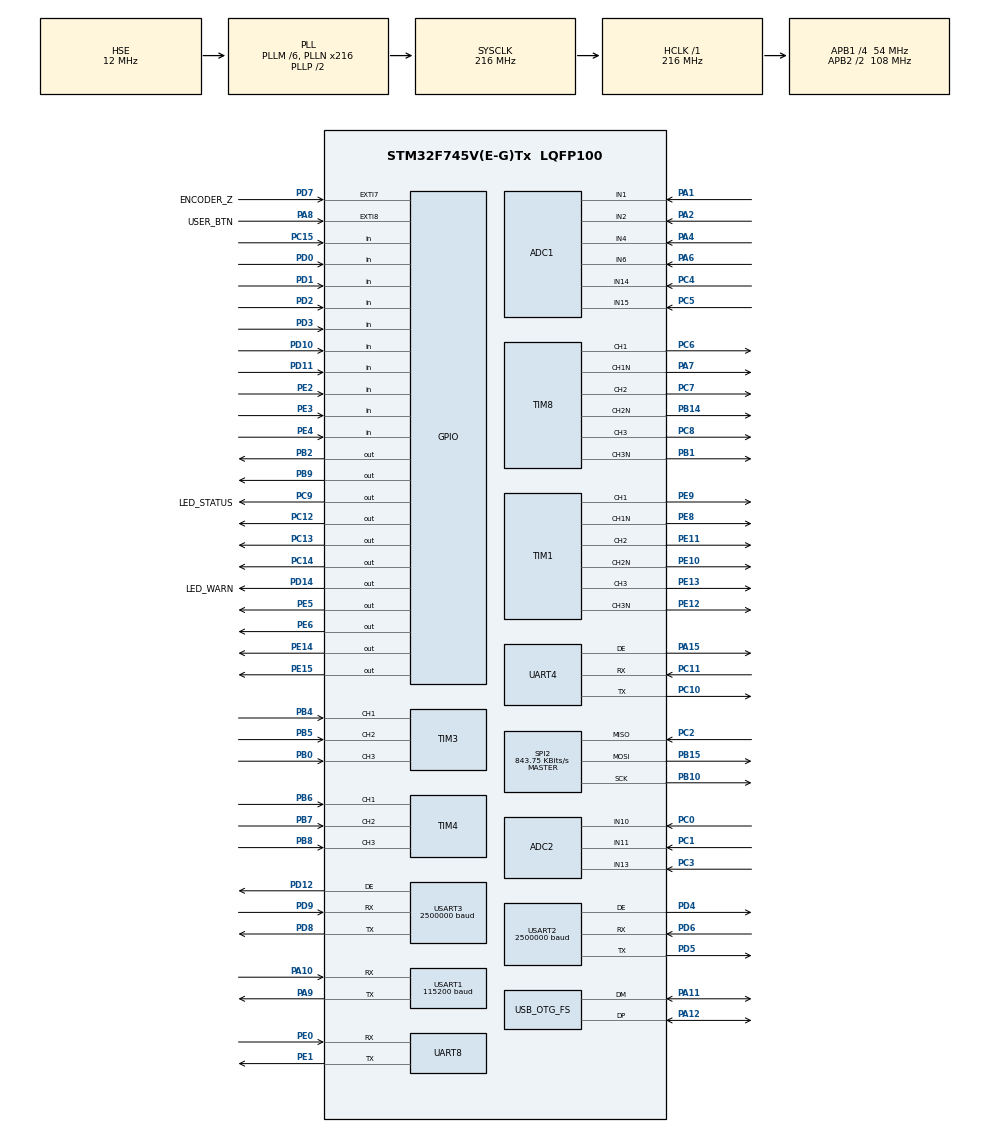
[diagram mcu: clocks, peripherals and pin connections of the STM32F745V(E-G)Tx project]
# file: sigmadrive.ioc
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ADC1.Channel-0\#ChannelRegularConversion=ADC_CHANNEL_1
ADC1.Channel-1\#ChannelInjectedConversion=ADC_CHANNEL_1
ADC1.Channel-10\#ChannelInjectedConversion=ADC_CHANNEL_4
ADC1.Channel-2\#ChannelInjectedConversion=ADC_CHANNEL_2
ADC1.Channel-5\#ChannelRegularConversion=ADC_CHANNEL_2
ADC1.Channel-6\#ChannelRegularConversion=ADC_CHANNEL_4
ADC1.Channel-7\#ChannelRegularConversion=ADC_CHANNEL_6
ADC1.Channel-8\#ChannelRegularConversion=ADC_CHANNEL_14
ADC1.Channel-9\#ChannelRegularConversion=ADC_CHANNEL_15
ADC1.ContinuousConvMode=DISABLE
ADC1.DMAContinuousRequests=ENABLE
ADC1.EOCSelection=ADC_EOC_SINGLE_CONV
ADC1.ExternalTrigConv=ADC_EXTERNALTRIGCONV_T1_TRGO2
ADC1.ExternalTrigConvEdge=ADC_EXTERNALTRIGCONVEDGE_RISINGFALLING
ADC1.ExternalTrigInjecConv=ADC_EXTERNALTRIGINJECCONV_T1_TRGO2
ADC1.ExternalTrigInjecConvEdge=ADC_EXTERNALTRIGINJECCONVEDGE_RISINGFALLING
ADC1.InjNumberOfConversion=3
ADC1.InjectedConvMode=None
ADC1.InjectedOffset-1\#ChannelInjectedConversion=0
ADC1.InjectedOffset-10\#ChannelInjectedConversion=0
ADC1.InjectedOffset-2\#ChannelInjectedConversion=0
ADC1.InjectedRank-1\#ChannelInjectedConversion=1
ADC1.InjectedRank-10\#ChannelInjectedConversion=3
ADC1.InjectedRank-2\#ChannelInjectedConversion=2
ADC1.NbrOfConversion=6
ADC1.NbrOfConversionFlag=1
ADC1.Rank-0\#ChannelRegularConversion=1
ADC1.Rank-5\#ChannelRegularConversion=2
ADC1.Rank-6\#ChannelRegularConversion=3
ADC1.Rank-7\#ChannelRegularConversion=4
ADC1.Rank-8\#ChannelRegularConversion=5
ADC1.Rank-9\#ChannelRegularConversion=6
ADC1.SamplingTime-0\#ChannelRegularConversion=ADC_SAMPLETIME_15CYCLES
ADC1.SamplingTime-1\#ChannelInjectedConversion=ADC_SAMPLETIME_15CYCLES
ADC1.SamplingTime-10\#ChannelInjectedConversion=ADC_SAMPLETIME_15CYCLES
ADC1.SamplingTime-2\#ChannelInjectedConversion=ADC_SAMPLETIME_15CYCLES
ADC1.SamplingTime-5\#ChannelRegularConversion=ADC_SAMPLETIME_15CYCLES
ADC1.SamplingTime-6\#ChannelRegularConversion=ADC_SAMPLETIME_15CYCLES
ADC1.SamplingTime-7\#ChannelRegularConversion=ADC_SAMPLETIME_15CYCLES
ADC1.SamplingTime-8\#ChannelRegularConversion=ADC_SAMPLETIME_15CYCLES
ADC1.SamplingTime-9\#ChannelRegularConversion=ADC_SAMPLETIME_15CYCLES
ADC1.master=1
ADC2.Channel-10\#ChannelRegularConversion=ADC_CHANNEL_13
ADC2.Channel-11\#ChannelInjectedConversion=ADC_CHANNEL_10
ADC2.Channel-12\#ChannelInjectedConversion=ADC_CHANNEL_11
ADC2.Channel-13\#ChannelInjectedConversion=ADC_CHANNEL_13
ADC2.Channel-8\#ChannelRegularConversion=ADC_CHANNEL_10
ADC2.Channel-9\#ChannelRegularConversion=ADC_CHANNEL_11
ADC2.DMAContinuousRequests=ENABLE
ADC2.ExternalTrigConv=ADC_EXTERNALTRIGCONV_T8_TRGO2
ADC2.ExternalTrigConvEdge=ADC_EXTERNALTRIGCONVEDGE_RISINGFALLING
ADC2.ExternalTrigInjecConv=ADC_EXTERNALTRIGINJECCONV_T8_TRGO2
ADC2.ExternalTrigInjecConvEdge=ADC_EXTERNALTRIGINJECCONVEDGE_RISINGFALLING
ADC2.InjNumberOfConversion=3
ADC2.InjectedOffset-11\#ChannelInjectedConversion=0
ADC2.InjectedOffset-12\#ChannelInjectedConversion=0
ADC2.InjectedOffset-13\#ChannelInjectedConversion=0
ADC2.InjectedRank-11\#ChannelInjectedConversion=1
ADC2.InjectedRank-12\#ChannelInjectedConversion=2
ADC2.InjectedRank-13\#ChannelInjectedConversion=3
ADC2.NbrOfConversion=3
ADC2.NbrOfConversionFlag=1
ADC2.Rank-10\#ChannelRegularConversion=3
ADC2.Rank-8\#ChannelRegularConversion=1
ADC2.Rank-9\#ChannelRegularConversion=2
ADC2.SamplingTime-10\#ChannelRegularConversion=ADC_SAMPLETIME_15CYCLES
ADC2.SamplingTime-11\#ChannelInjectedConversion=ADC_SAMPLETIME_15CYCLES
ADC2.SamplingTime-12\#ChannelInjectedConversion=ADC_SAMPLETIME_15CYCLES
ADC2.SamplingTime-13\#ChannelInjectedConversion=ADC_SAMPLETIME_15CYCLES
ADC2.SamplingTime-8\#ChannelRegularConversion=ADC_SAMPLETIME_15CYCLES
ADC2.SamplingTime-9\#ChannelRegularConversion=ADC_SAMPLETIME_15CYCLES
ADC2.ScanConvMode=ADC_SCAN_ENABLE
ADC3.Channel-2\#ChannelRegularConversion=ADC_CHANNEL_2
ADC3.Channel-3\#ChannelInjectedConversion=ADC_CHANNEL_2
ADC3.ExternalTrigInjecConv=ADC_EXTERNALTRIGINJECCONV_T1_TRGO
ADC3.ExternalTrigInjecConvEdge=ADC_EXTERNALTRIGINJECCONVEDGE_RISINGFALLING
ADC3.InjNumberOfConversion=1
ADC3.InjectedOffset-3\#ChannelInjectedConversion=0
ADC3.InjectedRank-3\#ChannelInjectedConversion=1
ADC3.NbrOfConversion=1
ADC3.NbrOfConversionFlag=1
ADC3.Rank-2\#ChannelRegularConversion=1
ADC3.SamplingTime-2\#ChannelRegularConversion=ADC_SAMPLETIME_3CYCLES
ADC3.SamplingTime-3\#ChannelInjectedConversion=ADC_SAMPLETIME_15CYCLES
CORTEX_M7.CPU_DCache=Disabled
CORTEX_M7.CPU_ICache=Enabled
CORTEX_M7.PREFETCH_ENABLE=1
Dma.ADC1.2.Direction=DMA_PERIPH_TO_MEMORY
Dma.ADC1.2.FIFOMode=DMA_FIFOMODE_ENABLE
Dma.ADC1.2.FIFOThreshold=DMA_FIFO_THRESHOLD_HALFFULL
Dma.ADC1.2.Instance=DMA2_Stream0
Dma.ADC1.2.MemBurst=DMA_MBURST_SINGLE
Dma.ADC1.2.MemDataAlignment=DMA_MDATAALIGN_WORD
Dma.ADC1.2.MemInc=DMA_MINC_ENABLE
Dma.ADC1.2.Mode=DMA_CIRCULAR
Dma.ADC1.2.PeriphBurst=DMA_PBURST_SINGLE
Dma.ADC1.2.PeriphDataAlignment=DMA_PDATAALIGN_WORD
Dma.ADC1.2.PeriphInc=DMA_PINC_DISABLE
Dma.ADC1.2.Priority=DMA_PRIORITY_HIGH
Dma.ADC2.5.Direction=DMA_PERIPH_TO_MEMORY
Dma.ADC2.5.FIFOMode=DMA_FIFOMODE_ENABLE
Dma.ADC2.5.FIFOThreshold=DMA_FIFO_THRESHOLD_FULL
Dma.ADC2.5.Instance=DMA2_Stream2
Dma.ADC2.5.MemBurst=DMA_MBURST_SINGLE
Dma.ADC2.5.MemDataAlignment=DMA_MDATAALIGN_WORD
Dma.ADC2.5.MemInc=DMA_MINC_ENABLE
Dma.ADC2.5.Mode=DMA_CIRCULAR
Dma.ADC2.5.PeriphBurst=DMA_PBURST_SINGLE
Dma.ADC2.5.PeriphDataAlignment=DMA_PDATAALIGN_WORD
Dma.ADC2.5.PeriphInc=DMA_PINC_DISABLE
Dma.ADC2.5.Priority=DMA_PRIORITY_LOW
Dma.Request0=USART1_TX
Dma.Request1=USART1_RX
Dma.Request2=ADC1
Dma.Request3=USART3_RX
Dma.Request4=USART2_RX
Dma.Request5=ADC2
Dma.Request6=UART4_RX
Dma.Request7=UART4_TX
Dma.Request8=UART8_TX
Dma.Request9=UART8_RX
Dma.UART4_RX.6.Direction=DMA_PERIPH_TO_MEMORY
Dma.UART4_RX.6.FIFOMode=DMA_FIFOMODE_DISABLE
Dma.UART4_RX.6.Instance=DMA1_Stream2
Dma.UART4_RX.6.MemDataAlignment=DMA_MDATAALIGN_BYTE
Dma.UART4_RX.6.MemInc=DMA_MINC_ENABLE
Dma.UART4_RX.6.Mode=DMA_CIRCULAR
Dma.UART4_RX.6.PeriphDataAlignment=DMA_PDATAALIGN_BYTE
Dma.UART4_RX.6.PeriphInc=DMA_PINC_DISABLE
Dma.UART4_RX.6.Priority=DMA_PRIORITY_LOW
Dma.UART4_TX.7.Direction=DMA_MEMORY_TO_PERIPH
Dma.UART4_TX.7.FIFOMode=DMA_FIFOMODE_DISABLE
Dma.UART4_TX.7.Instance=DMA1_Stream4
Dma.UART4_TX.7.MemDataAlignment=DMA_MDATAALIGN_BYTE
Dma.UART4_TX.7.MemInc=DMA_MINC_ENABLE
Dma.UART4_TX.7.Mode=DMA_NORMAL
Dma.UART4_TX.7.PeriphDataAlignment=DMA_PDATAALIGN_BYTE
Dma.UART4_TX.7.PeriphInc=DMA_PINC_DISABLE
Dma.UART4_TX.7.Priority=DMA_PRIORITY_LOW
Dma.UART8_RX.9.Direction=DMA_PERIPH_TO_MEMORY
Dma.UART8_RX.9.FIFOMode=DMA_FIFOMODE_DISABLE
Dma.UART8_RX.9.Instance=DMA1_Stream6
Dma.UART8_RX.9.MemDataAlignment=DMA_MDATAALIGN_BYTE
Dma.UART8_RX.9.MemInc=DMA_MINC_ENABLE
Dma.UART8_RX.9.Mode=DMA_CIRCULAR
Dma.UART8_RX.9.PeriphDataAlignment=DMA_PDATAALIGN_BYTE
Dma.UART8_RX.9.PeriphInc=DMA_PINC_DISABLE
Dma.UART8_RX.9.Priority=DMA_PRIORITY_LOW
Dma.UART8_TX.8.Direction=DMA_MEMORY_TO_PERIPH
Dma.UART8_TX.8.FIFOMode=DMA_FIFOMODE_DISABLE
Dma.UART8_TX.8.Instance=DMA1_Stream0
Dma.UART8_TX.8.MemDataAlignment=DMA_MDATAALIGN_BYTE
Dma.UART8_TX.8.MemInc=DMA_MINC_ENABLE
Dma.UART8_TX.8.Mode=DMA_NORMAL
Dma.UART8_TX.8.PeriphDataAlignment=DMA_PDATAALIGN_BYTE
Dma.UART8_TX.8.PeriphInc=DMA_PINC_DISABLE
Dma.UART8_TX.8.Priority=DMA_PRIORITY_LOW
Dma.USART1_RX.1.Direction=DMA_PERIPH_TO_MEMORY
Dma.USART1_RX.1.FIFOMode=DMA_FIFOMODE_DISABLE
Dma.USART1_RX.1.Instance=DMA2_Stream5
Dma.USART1_RX.1.MemDataAlignment=DMA_MDATAALIGN_BYTE
Dma.USART1_RX.1.MemInc=DMA_MINC_ENABLE
Dma.USART1_RX.1.Mode=DMA_CIRCULAR
Dma.USART1_RX.1.PeriphDataAlignment=DMA_PDATAALIGN_BYTE
Dma.USART1_RX.1.PeriphInc=DMA_PINC_DISABLE
Dma.USART1_RX.1.Priority=DMA_PRIORITY_LOW
Dma.USART1_TX.0.Direction=DMA_MEMORY_TO_PERIPH
Dma.USART1_TX.0.FIFOMode=DMA_FIFOMODE_DISABLE
Dma.USART1_TX.0.Instance=DMA2_Stream7
Dma.USART1_TX.0.MemDataAlignment=DMA_MDATAALIGN_BYTE
Dma.USART1_TX.0.MemInc=DMA_MINC_ENABLE
Dma.USART1_TX.0.Mode=DMA_NORMAL
Dma.USART1_TX.0.PeriphDataAlignment=DMA_PDATAALIGN_BYTE
Dma.USART1_TX.0.PeriphInc=DMA_PINC_DISABLE
Dma.USART1_TX.0.Priority=DMA_PRIORITY_LOW
Dma.USART2_RX.4.Direction=DMA_PERIPH_TO_MEMORY
Dma.USART2_RX.4.FIFOMode=DMA_FIFOMODE_DISABLE
Dma.USART2_RX.4.Instance=DMA1_Stream5
Dma.USART2_RX.4.MemDataAlignment=DMA_MDATAALIGN_BYTE
Dma.USART2_RX.4.MemInc=DMA_MINC_ENABLE
Dma.USART2_RX.4.Mode=DMA_NORMAL
Dma.USART2_RX.4.PeriphDataAlignment=DMA_PDATAALIGN_BYTE
Dma.USART2_RX.4.PeriphInc=DMA_PINC_DISABLE
Dma.USART2_RX.4.Priority=DMA_PRIORITY_VERY_HIGH
Dma.USART3_RX.3.Direction=DMA_PERIPH_TO_MEMORY
Dma.USART3_RX.3.FIFOMode=DMA_FIFOMODE_DISABLE
Dma.USART3_RX.3.Instance=DMA1_Stream1
Dma.USART3_RX.3.MemDataAlignment=DMA_MDATAALIGN_BYTE
Dma.USART3_RX.3.MemInc=DMA_MINC_ENABLE
Dma.USART3_RX.3.Mode=DMA_NORMAL
Dma.USART3_RX.3.PeriphDataAlignment=DMA_PDATAALIGN_BYTE
Dma.USART3_RX.3.PeriphInc=DMA_PINC_DISABLE
Dma.USART3_RX.3.Priority=DMA_PRIORITY_VERY_HIGH
FREERTOS.HEAP_NUMBER=3
FREERTOS.Tasks01=defaultTask,24,2048,StartDefaultTask,Default,NULL,Dynamic,NULL,NULL
FREERTOS.configMINIMAL_STACK_SIZE=1024
Mcu.Family=STM32F7
Mcu.Name=STM32F745V(E-G)Tx
Mcu.Package=LQFP100
Mcu.UserConstants=TIM1_PERIOD_CLOCKS,5400;TIM1_RCR,0;SYSTEM_CORE_CLOCK,216000000
NVIC.ADC_IRQn=true\:5\:0\:false\:false\:true\:true\:true\:true\:true
NVIC.DMA1_Stream0_IRQn=true\:5\:0\:false\:false\:true\:true\:false\:true\:true
NVIC.DMA1_Stream1_IRQn=true\:5\:0\:true\:false\:true\:false\:false\:true\:true
NVIC.DMA1_Stream2_IRQn=true\:5\:0\:true\:false\:true\:false\:false\:true\:true
NVIC.DMA1_Stream4_IRQn=true\:5\:0\:true\:false\:true\:false\:false\:true\:true
NVIC.DMA1_Stream5_IRQn=true\:5\:0\:true\:false\:true\:false\:false\:true\:true
NVIC.DMA1_Stream6_IRQn=true\:5\:0\:true\:false\:true\:false\:false\:true\:true
NVIC.DMA2_Stream0_IRQn=true\:5\:0\:false\:false\:true\:true\:false\:true\:true
NVIC.DMA2_Stream2_IRQn=true\:5\:0\:false\:false\:true\:true\:false\:true\:true
NVIC.DMA2_Stream5_IRQn=true\:5\:0\:false\:false\:true\:true\:false\:true\:true
NVIC.DMA2_Stream7_IRQn=true\:5\:0\:false\:false\:true\:true\:false\:true\:true
NVIC.EXTI9_5_IRQn=true\:2\:0\:true\:false\:true\:false\:true\:true\:true
NVIC.OTG_FS_IRQn=true\:5\:0\:true\:false\:true\:false\:false\:true\:true
NVIC.PriorityGroup=NVIC_PRIORITYGROUP_4
NVIC.TIM1_UP_TIM10_IRQn=true\:5\:0\:true\:false\:true\:false\:true\:true\:true
NVIC.TIM2_IRQn=true\:5\:0\:false\:false\:true\:true\:true\:true\:true
NVIC.TIM5_IRQn=true\:5\:0\:false\:false\:true\:true\:true\:true\:true
NVIC.TIM7_IRQn=true\:0\:0\:false\:false\:true\:false\:false\:true\:true
NVIC.TimeBase=TIM7_IRQn
NVIC.TimeBaseIP=TIM7
NVIC.UART4_IRQn=true\:5\:0\:true\:false\:true\:false\:true\:true\:true
NVIC.UART8_IRQn=true\:5\:0\:true\:false\:true\:false\:true\:true\:true
NVIC.USART1_IRQn=true\:5\:0\:false\:false\:true\:true\:true\:true\:true
NVIC.USART2_IRQn=true\:1\:0\:true\:false\:true\:false\:true\:true\:true
NVIC.USART3_IRQn=true\:1\:0\:true\:false\:true\:false\:true\:true\:true
PA0/WKUP.Signal=S_TIM5_CH1
PA1.Signal=ADCx_IN1
PA10.Mode=Asynchronous
PA10.Signal=USART1_RX
PA11.Mode=Device_Only
PA11.Signal=USB_OTG_FS_DM
PA12.Mode=Device_Only
PA12.Signal=USB_OTG_FS_DP
PA15.Mode=Hardware Flow Control (RS485)
PA15.Signal=UART4_DE
PA2.Signal=ADCx_IN2
PA4.Signal=ADCx_IN4
PA5.Signal=S_TIM2_CH1_ETR
PA6.Signal=ADCx_IN6
PA7.Mode=PWM Generation1 CH1 CH1N
PA7.Signal=TIM8_CH1N
PA8.GPIO_Label=USER_BTN
PA8.GPIO_ModeDefaultEXTI=GPIO_MODE_IT_FALLING
PA8.Signal=GPXTI8
PA9.Mode=Asynchronous
PA9.Signal=USART1_TX
PB0.Signal=S_TIM3_CH3
PB1.Mode=PWM Generation3 CH3 CH3N
PB1.Signal=TIM8_CH3N
PB10.Mode=Full_Duplex_Master
PB10.Signal=SPI2_SCK
PB14.Mode=PWM Generation2 CH2 CH2N
PB14.Signal=TIM8_CH2N
PB15.Mode=Full_Duplex_Master
PB15.Signal=SPI2_MOSI
PB2.GPIO_PuPd=GPIO_PULLUP
PB2.PinState=GPIO_PIN_SET
PB2.Signal=GPIO_Output
PB4.Signal=S_TIM3_CH1
PB5.Signal=S_TIM3_CH2
PB6.Signal=S_TIM4_CH1
PB7.Signal=S_TIM4_CH2
PB8.Signal=S_TIM4_CH3
PB9.Signal=GPIO_Output
PC0.Signal=ADCx_IN10
PC1.Signal=ADCx_IN11
PC10.Mode=Asynchronous
PC10.Signal=UART4_TX
PC11.Mode=Asynchronous
PC11.Signal=UART4_RX
PC12.Signal=GPIO_Output
PC13.GPIO_PuPd=GPIO_PULLUP
PC13.PinState=GPIO_PIN_SET
PC13.Signal=GPIO_Output
PC14/OSC32_IN.GPIO_ModeDefaultOutputPP=GPIO_MODE_OUTPUT_PP
PC14/OSC32_IN.GPIO_PuPd=GPIO_PULLUP
PC14/OSC32_IN.GPIO_Speed=GPIO_SPEED_FREQ_LOW
PC14/OSC32_IN.PinState=GPIO_PIN_SET
PC14/OSC32_IN.Signal=GPIO_Output
PC15/OSC32_OUT.GPIO_PuPd=GPIO_PULLUP
PC15/OSC32_OUT.Signal=GPIO_Input
PC2.GPIO_PuPd=GPIO_PULLUP
PC2.Mode=Full_Duplex_Master
PC2.Signal=SPI2_MISO
PC3.Signal=ADCx_IN13
PC4.Signal=ADCx_IN14
PC5.Signal=ADCx_IN15
PC6.Signal=S_TIM8_CH1
PC7.Signal=S_TIM8_CH2
PC8.Signal=S_TIM8_CH3
PC9.GPIO_Label=LED_STATUS
PC9.PinState=GPIO_PIN_SET
PC9.Signal=GPIO_Output
PD0.Signal=GPIO_Input
PD1.Signal=GPIO_Input
PD10.Signal=GPIO_Input
PD11.Signal=GPIO_Input
PD12.Mode=Hardware Flow Control (RS485)
PD12.Signal=USART3_DE
PD14.GPIO_Label=LED_WARN
PD14.GPIO_PuPd=GPIO_PULLUP
PD14.GPIO_Speed=GPIO_SPEED_FREQ_LOW
PD14.PinState=GPIO_PIN_RESET
PD14.Signal=GPIO_Output
PD2.Signal=GPIO_Input
PD3.Signal=GPIO_Input
PD4.Mode=Hardware Flow Control (RS485)
PD4.Signal=USART2_DE
PD5.Mode=Asynchronous
PD5.Signal=USART2_TX
PD6.Mode=Asynchronous
PD6.Signal=USART2_RX
PD7.GPIO_Label=ENCODER_Z
PD7.GPIO_ModeDefaultEXTI=GPIO_MODE_IT_RISING
PD7.GPIO_PuPd=GPIO_PULLDOWN
PD7.Signal=GPXTI7
PD8.Mode=Asynchronous
PD8.Signal=USART3_TX
PD9.Mode=Asynchronous
PD9.Signal=USART3_RX
PE0.Mode=Asynchronous
PE0.Signal=UART8_RX
PE1.Mode=Asynchronous
PE1.Signal=UART8_TX
PE10.Mode=PWM Generation2 CH2 CH2N
PE10.Signal=TIM1_CH2N
PE11.Signal=S_TIM1_CH2
PE12.Mode=PWM Generation3 CH3 CH3N
PE12.Signal=TIM1_CH3N
PE13.Signal=S_TIM1_CH3
PE14.PinState=GPIO_PIN_RESET
PE14.Signal=GPIO_Output
PE15.GPIO_PuPd=GPIO_PULLUP
PE15.PinState=GPIO_PIN_SET
PE15.Signal=GPIO_Output
PE2.Signal=GPIO_Input
PE3.Signal=GPIO_Input
PE4.Signal=GPIO_Input
PE5.Signal=GPIO_Output
PE6.Signal=GPIO_Output
PE8.Mode=PWM Generation1 CH1 CH1N
PE8.Signal=TIM1_CH1N
PE9.Signal=S_TIM1_CH1
PH0/OSC_IN.Mode=HSE-External-Oscillator
PH0/OSC_IN.Signal=RCC_OSC_IN
PH1/OSC_OUT.Mode=HSE-External-Oscillator
PH1/OSC_OUT.Signal=RCC_OSC_OUT
ProjectManager.HeapSize=0x200
ProjectManager.StackSize=0x400
ProjectManager.TargetToolchain=Makefile
RCC.AHBFreq_Value=216000000
RCC.APB1CLKDivider=RCC_HCLK_DIV4
RCC.APB1Freq_Value=54000000
RCC.APB1TimFreq_Value=108000000
RCC.APB2CLKDivider=RCC_HCLK_DIV2
RCC.APB2Freq_Value=108000000
RCC.APB2TimFreq_Value=216000000
RCC.CortexFreq_Value=216000000
RCC.HCLKFreq_Value=216000000
RCC.HSE_VALUE=12000000
RCC.HSI_VALUE=16000000
RCC.LSE_VALUE=32768
RCC.PLLM=6
RCC.PLLN=216
RCC.PLLQ=9
RCC.SYSCLKFreq_VALUE=216000000
RCC.SYSCLKSource=RCC_SYSCLKSOURCE_PLLCLK
RCC.USBFreq_Value=48000000
RCC.VCOOutputFreq_Value=432000000
SH.ADCx_IN1.0=ADC1_IN1,IN1
SH.ADCx_IN10.0=ADC2_IN10,IN10
SH.ADCx_IN11.0=ADC2_IN11,IN11
SH.ADCx_IN13.0=ADC2_IN13,IN13
SH.ADCx_IN14.0=ADC1_IN14,IN14
SH.ADCx_IN15.0=ADC1_IN15,IN15
SH.ADCx_IN2.0=ADC1_IN2,IN2
SH.ADCx_IN2.1=ADC3_IN2,IN2
SH.ADCx_IN4.0=ADC1_IN4,IN4
SH.ADCx_IN6.0=ADC1_IN6,IN6
SH.S_TIM1_CH1.0=TIM1_CH1,PWM Generation1 CH1 CH1N
SH.S_TIM1_CH2.0=TIM1_CH2,PWM Generation2 CH2 CH2N
SH.S_TIM1_CH3.0=TIM1_CH3,PWM Generation3 CH3 CH3N
SH.S_TIM2_CH1_ETR.0=TIM2_CH1
SH.S_TIM3_CH1.0=TIM3_CH1,Input_Capture1_from_TI1
SH.S_TIM3_CH2.0=TIM3_CH2,Input_Capture2_from_TI2
SH.S_TIM3_CH3.0=TIM3_CH3,Input_Capture3_from_TI3
SH.S_TIM4_CH1.0=TIM4_CH1,Input_Capture1_from_TI1
SH.S_TIM4_CH2.0=TIM4_CH2,Input_Capture2_from_TI2
SH.S_TIM4_CH3.0=TIM4_CH3,Input_Capture3_from_TI3
SH.S_TIM5_CH1.0=TIM5_CH1
SH.S_TIM8_CH1.0=TIM8_CH1,PWM Generation1 CH1 CH1N
SH.S_TIM8_CH2.0=TIM8_CH2,PWM Generation2 CH2 CH2N
SH.S_TIM8_CH3.0=TIM8_CH3,PWM Generation3 CH3 CH3N
SPI2.BaudRatePrescaler=SPI_BAUDRATEPRESCALER_64
SPI2.CLKPhase=SPI_PHASE_2EDGE
SPI2.CRCCalculation=SPI_CRCCALCULATION_DISABLE
SPI2.CalculateBaudRate=843.75 KBits/s
SPI2.DataSize=SPI_DATASIZE_16BIT
SPI2.Direction=SPI_DIRECTION_2LINES
SPI2.Mode=SPI_MODE_MASTER
SPI2.VirtualType=VM_MASTER
TIM1.AutoReloadPreload=TIM_AUTORELOAD_PRELOAD_ENABLE
TIM1.Channel-PWM\ Generation1\ CH1\ CH1N=TIM_CHANNEL_1
TIM1.Channel-PWM\ Generation2\ CH2\ CH2N=TIM_CHANNEL_2
TIM1.Channel-PWM\ Generation3\ CH3\ CH3N=TIM_CHANNEL_3
TIM1.Channel-PWM\ Generation4\ No\ Output=TIM_CHANNEL_4
TIM1.CounterMode=TIM_COUNTERMODE_CENTERALIGNED3
TIM1.OCMode_PWM-PWM\ Generation1\ CH1\ CH1N=TIM_OCMODE_PWM2
TIM1.OCMode_PWM-PWM\ Generation2\ CH2\ CH2N=TIM_OCMODE_PWM2
TIM1.OCMode_PWM-PWM\ Generation3\ CH3\ CH3N=TIM_OCMODE_PWM2
TIM1.OCMode_PWM-PWM\ Generation4\ No\ Output=TIM_OCMODE_PWM2
TIM1.Period=TIM1_PERIOD_CLOCKS
TIM1.Pulse-PWM\ Generation1\ CH1\ CH1N=TIM1_PERIOD_CLOCKS/2
TIM1.Pulse-PWM\ Generation2\ CH2\ CH2N=TIM1_PERIOD_CLOCKS/2
TIM1.Pulse-PWM\ Generation3\ CH3\ CH3N=TIM1_PERIOD_CLOCKS/2
TIM1.Pulse-PWM\ Generation4\ No\ Output=1
TIM1.RepetitionCounter=TIM1_RCR
TIM1.TIM_MasterOutputTrigger=TIM_TRGO_ENABLE
TIM1.TIM_MasterOutputTrigger2=TIM_TRGO2_UPDATE
TIM12.Period=0xFFFF
TIM2.AutoReloadPreload=TIM_AUTORELOAD_PRELOAD_ENABLE
TIM2.Channel-Output\ Compare1\ No\ Output=TIM_CHANNEL_1
TIM2.Period=843750
TIM3.Channel-Input_Capture1_from_TI1=TIM_CHANNEL_1
TIM3.Channel-Input_Capture2_from_TI2=TIM_CHANNEL_2
TIM3.Channel-Input_Capture3_from_TI3=TIM_CHANNEL_3
TIM4.Channel-Input_Capture1_from_TI1=TIM_CHANNEL_1
TIM4.Channel-Input_Capture2_from_TI2=TIM_CHANNEL_2
TIM4.Channel-Input_Capture3_from_TI3=TIM_CHANNEL_3
TIM5.Channel-Output\ Compare1\ No\ Output=TIM_CHANNEL_1
TIM5.Period=843750
TIM8.AutoReloadPreload=TIM_AUTORELOAD_PRELOAD_ENABLE
TIM8.Channel-PWM\ Generation1\ CH1\ CH1N=TIM_CHANNEL_1
TIM8.Channel-PWM\ Generation2\ CH2\ CH2N=TIM_CHANNEL_2
TIM8.Channel-PWM\ Generation3\ CH3\ CH3N=TIM_CHANNEL_3
TIM8.CounterMode=TIM_COUNTERMODE_CENTERALIGNED3
TIM8.OCMode_PWM-PWM\ Generation1\ CH1\ CH1N=TIM_OCMODE_PWM2
TIM8.OCMode_PWM-PWM\ Generation2\ CH2\ CH2N=TIM_OCMODE_PWM2
TIM8.OCMode_PWM-PWM\ Generation3\ CH3\ CH3N=TIM_OCMODE_PWM2
TIM8.Period=TIM1_PERIOD_CLOCKS
TIM8.RepetitionCounter=TIM1_RCR
TIM8.TIM_MasterOutputTrigger=TIM_TRGO_ENABLE
TIM8.TIM_MasterOutputTrigger2=TIM_TRGO2_UPDATE
UART4.OverSampling=UART_OVERSAMPLING_16
UART8.DMADisableonRxErrorParam=UART_ADVFEATURE_DMA_ENABLEONRXERROR
USART1.BaudRate=115200
USART1.OverSampling=UART_OVERSAMPLING_8
USART1.VirtualMode-Asynchronous=VM_ASYNC
USART2.BaudRate=2500000
USART2.OverSampling=UART_OVERSAMPLING_8
USART2.UART_DEPolarity=UART_DE_POLARITY_HIGH
USART2.VirtualMode-Asynchronous=VM_ASYNC
USART2.VirtualMode-Hardware\ Flow\ Control\ (RS485)=VM_ASYNC
USART3.BaudRate=2500000
USART3.OverSampling=UART_OVERSAMPLING_8
USART3.VirtualMode-Asynchronous=VM_ASYNC
USART3.VirtualMode-Hardware\ Flow\ Control\ (RS485)=VM_ASYNC
USB_DEVICE.CLASS_NAME_FS=CDC
USB_DEVICE.PRODUCT_STRING_CDC_FS=SIGMADRIVE Virtual ComPort
USB_DEVICE.VirtualMode-CDC_FS=Cdc
USB_DEVICE.VirtualModeFS=Cdc_FS
USB_OTG_FS.VirtualMode=Device_Only
VP_FREERTOS_VS_CMSIS_V2.Mode=CMSIS_V2
VP_SYS_VS_tim7.Mode=TIM7
VP_TIM12_VS_ClockSourceINT.Mode=Internal
VP_TIM1_VS_ClockSourceINT.Mode=Internal
VP_TIM1_VS_no_output4.Mode=PWM Generation4 No Output
VP_TIM2_VS_ClockSourceINT.Mode=Internal
VP_TIM2_VS_no_output1.Mode=Output Compare1 No Output
VP_TIM3_VS_ClockSourceINT.Mode=Internal
VP_TIM4_VS_ClockSourceINT.Mode=Internal
VP_TIM5_VS_ClockSourceINT.Mode=Internal
VP_TIM5_VS_no_output1.Mode=Output Compare1 No Output
VP_TIM8_VS_ClockSourceINT.Mode=Internal
VP_TIM8_VS_ClockSourceITR.Mode=TriggerSource_ITR0
VP_TIM8_VS_ControllerModeTrigger.Mode=Trigger Mode
VP_USB_DEVICE_VS_USB_DEVICE_CDC_FS.Mode=CDC_FS
board=custom

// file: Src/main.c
/* USER CODE BEGIN Header */
/**
  ******************************************************************************
  * @file           : main.c
  * @brief          : Main program body
  ******************************************************************************
  * @attention
  *
  * <h2><center>&copy; Copyright (c) 2019 STMicroelectronics.
  * All rights reserved.</center></h2>
  *
  * This software component is licensed by ST under BSD 3-Clause license,
  * the "License"; You may not use this file except in compliance with the
  * License. You may obtain a copy of the License at:
  *                        opensource.org/licenses/BSD-3-Clause
  *
  ******************************************************************************
  */
/* USER CODE END Header */
#include "main.h"
#include "cmsis_os.h"
#include "usb_device.h"

/* USER CODE BEGIN Includes */
#include "application/appmain.h"
/* USER CODE END Includes */

/* USER CODE BEGIN PD */
void SD_TIM2_PeriodElapsedCallback(TIM_HandleTypeDef *htim);
void SD_TIM5_PeriodElapsedCallback(TIM_HandleTypeDef *htim);
/* USER CODE END PD */

ADC_HandleTypeDef hadc1;
ADC_HandleTypeDef hadc2;
ADC_HandleTypeDef hadc3;
DMA_HandleTypeDef hdma_adc1;
DMA_HandleTypeDef hdma_adc2;

SPI_HandleTypeDef hspi2;

TIM_HandleTypeDef htim1;
TIM_HandleTypeDef htim2;
TIM_HandleTypeDef htim3;
TIM_HandleTypeDef htim4;
TIM_HandleTypeDef htim5;
TIM_HandleTypeDef htim8;
TIM_HandleTypeDef htim12;

UART_HandleTypeDef huart4;
UART_HandleTypeDef huart8;
UART_HandleTypeDef huart1;
UART_HandleTypeDef huart2;
UART_HandleTypeDef huart3;
DMA_HandleTypeDef hdma_uart4_rx;
DMA_HandleTypeDef hdma_uart4_tx;
DMA_HandleTypeDef hdma_uart8_tx;
DMA_HandleTypeDef hdma_uart8_rx;
DMA_HandleTypeDef hdma_usart1_tx;
DMA_HandleTypeDef hdma_usart1_rx;
DMA_HandleTypeDef hdma_usart2_rx;
DMA_HandleTypeDef hdma_usart3_rx;

/* Definitions for defaultTask */
osThreadId_t defaultTaskHandle;
const osThreadAttr_t defaultTask_attributes = {
  .name = "defaultTask",
  .stack_size = 2048 * 4,
  .priority = (osPriority_t) osPriorityNormal,
};
/* USER CODE BEGIN PV */

struct _reent* _impure_data_ptr = NULL;

/* USER CODE END PV */

void SystemClock_Config(void);
static void MX_GPIO_Init(void);
static void MX_DMA_Init(void);
static void MX_USART1_UART_Init(void);
static void MX_TIM4_Init(void);
static void MX_ADC1_Init(void);
static void MX_TIM1_Init(void);
static void MX_ADC2_Init(void);
static void MX_ADC3_Init(void);
static void MX_USART3_UART_Init(void);
static void MX_TIM5_Init(void);
static void MX_TIM8_Init(void);
static void MX_TIM12_Init(void);
static void MX_USART2_UART_Init(void);
static void MX_SPI2_Init(void);
static void MX_UART4_Init(void);
static void MX_TIM2_Init(void);
static void MX_TIM3_Init(void);
static void MX_UART8_Init(void);
void StartDefaultTask(void *argument);

/* USER CODE BEGIN 0 */
void OC4_PWM_Override(TIM_HandleTypeDef* htim) {

    TIM_OC_InitTypeDef sConfigOC;
    sConfigOC.OCMode = TIM_OCMODE_PWM2;
    sConfigOC.Pulse = 1;
    sConfigOC.OCPolarity = TIM_OCPOLARITY_HIGH;
    sConfigOC.OCNPolarity = TIM_OCNPOLARITY_HIGH;
    sConfigOC.OCFastMode = TIM_OCFAST_DISABLE;
    sConfigOC.OCIdleState = TIM_OCIDLESTATE_RESET;
    sConfigOC.OCNIdleState = TIM_OCNIDLESTATE_RESET;

    HAL_TIM_OC_ConfigChannel(htim, &sConfigOC, TIM_CHANNEL_4);
}

/* USER CODE END 0 */

int main(void)
{
  /* USER CODE BEGIN 1 */

  SCB_InvalidateICache();
  /* USER CODE END 1 */

  /* Enable I-Cache---------------------------------------------------------*/
  SCB_EnableICache();

  /* MCU Configuration--------------------------------------------------------*/

  /* Reset of all peripherals, Initializes the Flash interface and the Systick. */
  HAL_Init();

  /* Configure the system clock */
  SystemClock_Config();

  /* Initialize all configured peripherals */
  MX_GPIO_Init();
  MX_DMA_Init();
  MX_USART1_UART_Init();
  MX_TIM4_Init();
  MX_ADC1_Init();
  MX_TIM1_Init();
  MX_ADC2_Init();
  MX_ADC3_Init();
  MX_USART3_UART_Init();
  MX_TIM5_Init();
  MX_TIM8_Init();
  MX_TIM12_Init();
  MX_USART2_UART_Init();
  MX_SPI2_Init();
  MX_UART4_Init();
  MX_TIM2_Init();
  MX_TIM3_Init();
  MX_UART8_Init();
  /* USER CODE BEGIN 2 */
  /*
   * Undo what MX_DMA_Init does, because
   * CubeMX doesn't allow to unselect the DMA IRQ
   */
  HAL_NVIC_DisableIRQ(DMA2_Stream0_IRQn);

  /*
   * Set the Encoder index IRQ
   */
  HAL_NVIC_SetPriority(EXTI9_5_IRQn, 2, 0);

  /*
   * Save the original newlib _reent context
   */
  _impure_data_ptr = _impure_ptr;

  /* USER CODE END 2 */

  /* Init scheduler */
  osKernelInitialize();

  /* Create the thread(s) */
  /* creation of defaultTask */
  defaultTaskHandle = osThreadNew(StartDefaultTask, NULL, &defaultTask_attributes);

  /* Start scheduler */
  osKernelStart();

  /* We should never get here as control is now taken by the scheduler */
  /* Infinite loop */
  /* USER CODE BEGIN WHILE */
//  application_main();
  while (1)
  {
    /* USER CODE END WHILE */

  }
}

void SystemClock_Config(void)
{
  RCC_OscInitTypeDef RCC_OscInitStruct = {0};
  RCC_ClkInitTypeDef RCC_ClkInitStruct = {0};

  /** Configure the main internal regulator output voltage
  */
  __HAL_RCC_PWR_CLK_ENABLE();
  __HAL_PWR_VOLTAGESCALING_CONFIG(PWR_REGULATOR_VOLTAGE_SCALE1);

  /** Initializes the RCC Oscillators according to the specified parameters
  * in the RCC_OscInitTypeDef structure.
  */
  RCC_OscInitStruct.OscillatorType = RCC_OSCILLATORTYPE_HSE;
  RCC_OscInitStruct.HSEState = RCC_HSE_ON;
  RCC_OscInitStruct.PLL.PLLState = RCC_PLL_ON;
  RCC_OscInitStruct.PLL.PLLSource = RCC_PLLSOURCE_HSE;
  RCC_OscInitStruct.PLL.PLLM = 6;
  RCC_OscInitStruct.PLL.PLLN = 216;
  RCC_OscInitStruct.PLL.PLLP = RCC_PLLP_DIV2;
  RCC_OscInitStruct.PLL.PLLQ = 9;
  if (HAL_RCC_OscConfig(&RCC_OscInitStruct) != HAL_OK)
  {
    Error_Handler();
  }

  /** Activate the Over-Drive mode
  */
  if (HAL_PWREx_EnableOverDrive() != HAL_OK)
  {
    Error_Handler();
  }

  /** Initializes the CPU, AHB and APB buses clocks
  */
  RCC_ClkInitStruct.ClockType = RCC_CLOCKTYPE_HCLK|RCC_CLOCKTYPE_SYSCLK
                              |RCC_CLOCKTYPE_PCLK1|RCC_CLOCKTYPE_PCLK2;
  RCC_ClkInitStruct.SYSCLKSource = RCC_SYSCLKSOURCE_PLLCLK;
  RCC_ClkInitStruct.AHBCLKDivider = RCC_SYSCLK_DIV1;
  RCC_ClkInitStruct.APB1CLKDivider = RCC_HCLK_DIV4;
  RCC_ClkInitStruct.APB2CLKDivider = RCC_HCLK_DIV2;

  if (HAL_RCC_ClockConfig(&RCC_ClkInitStruct, FLASH_LATENCY_7) != HAL_OK)
  {
    Error_Handler();
  }
}

static void MX_ADC1_Init(void)
{

  ADC_ChannelConfTypeDef sConfig = {0};
  ADC_InjectionConfTypeDef sConfigInjected = {0};

  /** Configure the global features of the ADC (Clock, Resolution, Data Alignment and number of conversion)
  */
  hadc1.Instance = ADC1;
  hadc1.Init.ClockPrescaler = ADC_CLOCK_SYNC_PCLK_DIV4;
  hadc1.Init.Resolution = ADC_RESOLUTION_12B;
  hadc1.Init.ScanConvMode = ADC_SCAN_ENABLE;
  hadc1.Init.ContinuousConvMode = DISABLE;
  hadc1.Init.DiscontinuousConvMode = DISABLE;
  hadc1.Init.ExternalTrigConvEdge = ADC_EXTERNALTRIGCONVEDGE_RISINGFALLING;
  hadc1.Init.ExternalTrigConv = ADC_EXTERNALTRIGCONV_T1_TRGO2;
  hadc1.Init.DataAlign = ADC_DATAALIGN_RIGHT;
  hadc1.Init.NbrOfConversion = 6;
  hadc1.Init.DMAContinuousRequests = ENABLE;
  hadc1.Init.EOCSelection = ADC_EOC_SINGLE_CONV;
  if (HAL_ADC_Init(&hadc1) != HAL_OK)
  {
    Error_Handler();
  }

  /** Configure for the selected ADC regular channel its corresponding rank in the sequencer and its sample time.
  */
  sConfig.Channel = ADC_CHANNEL_1;
  sConfig.Rank = ADC_REGULAR_RANK_1;
  sConfig.SamplingTime = ADC_SAMPLETIME_15CYCLES;
  if (HAL_ADC_ConfigChannel(&hadc1, &sConfig) != HAL_OK)
  {
    Error_Handler();
  }

  /** Configure for the selected ADC regular channel its corresponding rank in the sequencer and its sample time.
  */
  sConfig.Channel = ADC_CHANNEL_2;
  sConfig.Rank = ADC_REGULAR_RANK_2;
  if (HAL_ADC_ConfigChannel(&hadc1, &sConfig) != HAL_OK)
  {
    Error_Handler();
  }

  /** Configure for the selected ADC regular channel its corresponding rank in the sequencer and its sample time.
  */
  sConfig.Channel = ADC_CHANNEL_4;
  sConfig.Rank = ADC_REGULAR_RANK_3;
  if (HAL_ADC_ConfigChannel(&hadc1, &sConfig) != HAL_OK)
  {
    Error_Handler();
  }

  /** Configure for the selected ADC regular channel its corresponding rank in the sequencer and its sample time.
  */
  sConfig.Channel = ADC_CHANNEL_6;
  sConfig.Rank = ADC_REGULAR_RANK_4;
  if (HAL_ADC_ConfigChannel(&hadc1, &sConfig) != HAL_OK)
  {
    Error_Handler();
  }

  /** Configure for the selected ADC regular channel its corresponding rank in the sequencer and its sample time.
  */
  sConfig.Channel = ADC_CHANNEL_14;
  sConfig.Rank = ADC_REGULAR_RANK_5;
  if (HAL_ADC_ConfigChannel(&hadc1, &sConfig) != HAL_OK)
  {
    Error_Handler();
  }

  /** Configure for the selected ADC regular channel its corresponding rank in the sequencer and its sample time.
  */
  sConfig.Channel = ADC_CHANNEL_15;
  sConfig.Rank = ADC_REGULAR_RANK_6;
  if (HAL_ADC_ConfigChannel(&hadc1, &sConfig) != HAL_OK)
  {
    Error_Handler();
  }

  /** Configures for the selected ADC injected channel its corresponding rank in the sequencer and its sample time
  */
  sConfigInjected.InjectedChannel = ADC_CHANNEL_1;
  sConfigInjected.InjectedRank = ADC_INJECTED_RANK_1;
  sConfigInjected.InjectedNbrOfConversion = 3;
  sConfigInjected.InjectedSamplingTime = ADC_SAMPLETIME_15CYCLES;
  sConfigInjected.ExternalTrigInjecConvEdge = ADC_EXTERNALTRIGINJECCONVEDGE_RISINGFALLING;
  sConfigInjected.ExternalTrigInjecConv = ADC_EXTERNALTRIGINJECCONV_T1_TRGO2;
  sConfigInjected.AutoInjectedConv = DISABLE;
  sConfigInjected.InjectedDiscontinuousConvMode = DISABLE;
  sConfigInjected.InjectedOffset = 0;
  if (HAL_ADCEx_InjectedConfigChannel(&hadc1, &sConfigInjected) != HAL_OK)
  {
    Error_Handler();
  }

  /** Configures for the selected ADC injected channel its corresponding rank in the sequencer and its sample time
  */
  sConfigInjected.InjectedChannel = ADC_CHANNEL_2;
  sConfigInjected.InjectedRank = ADC_INJECTED_RANK_2;
  if (HAL_ADCEx_InjectedConfigChannel(&hadc1, &sConfigInjected) != HAL_OK)
  {
    Error_Handler();
  }

  /** Configures for the selected ADC injected channel its corresponding rank in the sequencer and its sample time
  */
  sConfigInjected.InjectedChannel = ADC_CHANNEL_4;
  sConfigInjected.InjectedRank = ADC_INJECTED_RANK_3;
  if (HAL_ADCEx_InjectedConfigChannel(&hadc1, &sConfigInjected) != HAL_OK)
  {
    Error_Handler();
  }

}

static void MX_ADC2_Init(void)
{

  ADC_ChannelConfTypeDef sConfig = {0};
  ADC_InjectionConfTypeDef sConfigInjected = {0};

  /** Configure the global features of the ADC (Clock, Resolution, Data Alignment and number of conversion)
  */
  hadc2.Instance = ADC2;
  hadc2.Init.ClockPrescaler = ADC_CLOCK_SYNC_PCLK_DIV4;
  hadc2.Init.Resolution = ADC_RESOLUTION_12B;
  hadc2.Init.ScanConvMode = ADC_SCAN_ENABLE;
  hadc2.Init.ContinuousConvMode = DISABLE;
  hadc2.Init.DiscontinuousConvMode = DISABLE;
  hadc2.Init.ExternalTrigConvEdge = ADC_EXTERNALTRIGCONVEDGE_RISINGFALLING;
  hadc2.Init.ExternalTrigConv = ADC_EXTERNALTRIGCONV_T8_TRGO2;
  hadc2.Init.DataAlign = ADC_DATAALIGN_RIGHT;
  hadc2.Init.NbrOfConversion = 3;
  hadc2.Init.DMAContinuousRequests = ENABLE;
  hadc2.Init.EOCSelection = ADC_EOC_SINGLE_CONV;
  if (HAL_ADC_Init(&hadc2) != HAL_OK)
  {
    Error_Handler();
  }

  /** Configure for the selected ADC regular channel its corresponding rank in the sequencer and its sample time.
  */
  sConfig.Channel = ADC_CHANNEL_10;
  sConfig.Rank = ADC_REGULAR_RANK_1;
  sConfig.SamplingTime = ADC_SAMPLETIME_15CYCLES;
  if (HAL_ADC_ConfigChannel(&hadc2, &sConfig) != HAL_OK)
  {
    Error_Handler();
  }

  /** Configure for the selected ADC regular channel its corresponding rank in the sequencer and its sample time.
  */
  sConfig.Channel = ADC_CHANNEL_11;
  sConfig.Rank = ADC_REGULAR_RANK_2;
  if (HAL_ADC_ConfigChannel(&hadc2, &sConfig) != HAL_OK)
  {
    Error_Handler();
  }

  /** Configure for the selected ADC regular channel its corresponding rank in the sequencer and its sample time.
  */
  sConfig.Channel = ADC_CHANNEL_13;
  sConfig.Rank = ADC_REGULAR_RANK_3;
  if (HAL_ADC_ConfigChannel(&hadc2, &sConfig) != HAL_OK)
  {
    Error_Handler();
  }

  /** Configures for the selected ADC injected channel its corresponding rank in the sequencer and its sample time
  */
  sConfigInjected.InjectedChannel = ADC_CHANNEL_10;
  sConfigInjected.InjectedRank = ADC_INJECTED_RANK_1;
  sConfigInjected.InjectedNbrOfConversion = 3;
  sConfigInjected.InjectedSamplingTime = ADC_SAMPLETIME_15CYCLES;
  sConfigInjected.ExternalTrigInjecConvEdge = ADC_EXTERNALTRIGINJECCONVEDGE_RISINGFALLING;
  sConfigInjected.ExternalTrigInjecConv = ADC_EXTERNALTRIGINJECCONV_T8_TRGO2;
  sConfigInjected.AutoInjectedConv = DISABLE;
  sConfigInjected.InjectedDiscontinuousConvMode = DISABLE;
  sConfigInjected.InjectedOffset = 0;
  if (HAL_ADCEx_InjectedConfigChannel(&hadc2, &sConfigInjected) != HAL_OK)
  {
    Error_Handler();
  }

  /** Configures for the selected ADC injected channel its corresponding rank in the sequencer and its sample time
  */
  sConfigInjected.InjectedChannel = ADC_CHANNEL_11;
  sConfigInjected.InjectedRank = ADC_INJECTED_RANK_2;
  if (HAL_ADCEx_InjectedConfigChannel(&hadc2, &sConfigInjected) != HAL_OK)
  {
    Error_Handler();
  }

  /** Configures for the selected ADC injected channel its corresponding rank in the sequencer and its sample time
  */
  sConfigInjected.InjectedChannel = ADC_CHANNEL_13;
  sConfigInjected.InjectedRank = ADC_INJECTED_RANK_3;
  if (HAL_ADCEx_InjectedConfigChannel(&hadc2, &sConfigInjected) != HAL_OK)
  {
    Error_Handler();
  }

}

static void MX_ADC3_Init(void)
{

  ADC_ChannelConfTypeDef sConfig = {0};
  ADC_InjectionConfTypeDef sConfigInjected = {0};

  /** Configure the global features of the ADC (Clock, Resolution, Data Alignment and number of conversion)
  */
  hadc3.Instance = ADC3;
  hadc3.Init.ClockPrescaler = ADC_CLOCK_SYNC_PCLK_DIV4;
  hadc3.Init.Resolution = ADC_RESOLUTION_12B;
  hadc3.Init.ScanConvMode = ADC_SCAN_DISABLE;
  hadc3.Init.ContinuousConvMode = DISABLE;
  hadc3.Init.DiscontinuousConvMode = DISABLE;
  hadc3.Init.ExternalTrigConvEdge = ADC_EXTERNALTRIGCONVEDGE_NONE;
  hadc3.Init.ExternalTrigConv = ADC_SOFTWARE_START;
  hadc3.Init.DataAlign = ADC_DATAALIGN_RIGHT;
  hadc3.Init.NbrOfConversion = 1;
  hadc3.Init.DMAContinuousRequests = DISABLE;
  hadc3.Init.EOCSelection = ADC_EOC_SINGLE_CONV;
  if (HAL_ADC_Init(&hadc3) != HAL_OK)
  {
    Error_Handler();
  }

  /** Configure for the selected ADC regular channel its corresponding rank in the sequencer and its sample time.
  */
  sConfig.Channel = ADC_CHANNEL_2;
  sConfig.Rank = ADC_REGULAR_RANK_1;
  sConfig.SamplingTime = ADC_SAMPLETIME_3CYCLES;
  if (HAL_ADC_ConfigChannel(&hadc3, &sConfig) != HAL_OK)
  {
    Error_Handler();
  }

  /** Configures for the selected ADC injected channel its corresponding rank in the sequencer and its sample time
  */
  sConfigInjected.InjectedChannel = ADC_CHANNEL_2;
  sConfigInjected.InjectedRank = ADC_INJECTED_RANK_1;
  sConfigInjected.InjectedNbrOfConversion = 1;
  sConfigInjected.InjectedSamplingTime = ADC_SAMPLETIME_15CYCLES;
  sConfigInjected.ExternalTrigInjecConvEdge = ADC_EXTERNALTRIGINJECCONVEDGE_RISINGFALLING;
  sConfigInjected.ExternalTrigInjecConv = ADC_EXTERNALTRIGINJECCONV_T1_TRGO;
  sConfigInjected.AutoInjectedConv = DISABLE;
  sConfigInjected.InjectedDiscontinuousConvMode = DISABLE;
  sConfigInjected.InjectedOffset = 0;
  if (HAL_ADCEx_InjectedConfigChannel(&hadc3, &sConfigInjected) != HAL_OK)
  {
    Error_Handler();
  }

}

static void MX_SPI2_Init(void)
{

  /* SPI2 parameter configuration*/
  hspi2.Instance = SPI2;
  hspi2.Init.Mode = SPI_MODE_MASTER;
  hspi2.Init.Direction = SPI_DIRECTION_2LINES;
  hspi2.Init.DataSize = SPI_DATASIZE_16BIT;
  hspi2.Init.CLKPolarity = SPI_POLARITY_LOW;
  hspi2.Init.CLKPhase = SPI_PHASE_2EDGE;
  hspi2.Init.NSS = SPI_NSS_SOFT;
  hspi2.Init.BaudRatePrescaler = SPI_BAUDRATEPRESCALER_64;
  hspi2.Init.FirstBit = SPI_FIRSTBIT_MSB;
  hspi2.Init.TIMode = SPI_TIMODE_DISABLE;
  hspi2.Init.CRCCalculation = SPI_CRCCALCULATION_DISABLE;
  hspi2.Init.CRCPolynomial = 7;
  hspi2.Init.CRCLength = SPI_CRC_LENGTH_DATASIZE;
  hspi2.Init.NSSPMode = SPI_NSS_PULSE_DISABLE;
  if (HAL_SPI_Init(&hspi2) != HAL_OK)
  {
    Error_Handler();
  }

}

static void MX_TIM1_Init(void)
{

  TIM_ClockConfigTypeDef sClockSourceConfig = {0};
  TIM_MasterConfigTypeDef sMasterConfig = {0};
  TIM_OC_InitTypeDef sConfigOC = {0};
  TIM_BreakDeadTimeConfigTypeDef sBreakDeadTimeConfig = {0};

  htim1.Instance = TIM1;
  htim1.Init.Prescaler = 0;
  htim1.Init.CounterMode = TIM_COUNTERMODE_CENTERALIGNED3;
  htim1.Init.Period = TIM1_PERIOD_CLOCKS;
  htim1.Init.ClockDivision = TIM_CLOCKDIVISION_DIV1;
  htim1.Init.RepetitionCounter = TIM1_RCR;
  htim1.Init.AutoReloadPreload = TIM_AUTORELOAD_PRELOAD_ENABLE;
  if (HAL_TIM_Base_Init(&htim1) != HAL_OK)
  {
    Error_Handler();
  }
  sClockSourceConfig.ClockSource = TIM_CLOCKSOURCE_INTERNAL;
  if (HAL_TIM_ConfigClockSource(&htim1, &sClockSourceConfig) != HAL_OK)
  {
    Error_Handler();
  }
  if (HAL_TIM_PWM_Init(&htim1) != HAL_OK)
  {
    Error_Handler();
  }
  sMasterConfig.MasterOutputTrigger = TIM_TRGO_ENABLE;
  sMasterConfig.MasterOutputTrigger2 = TIM_TRGO2_UPDATE;
  sMasterConfig.MasterSlaveMode = TIM_MASTERSLAVEMODE_DISABLE;
  if (HAL_TIMEx_MasterConfigSynchronization(&htim1, &sMasterConfig) != HAL_OK)
  {
    Error_Handler();
  }
  sConfigOC.OCMode = TIM_OCMODE_PWM2;
  sConfigOC.Pulse = TIM1_PERIOD_CLOCKS/2;
  sConfigOC.OCPolarity = TIM_OCPOLARITY_HIGH;
  sConfigOC.OCNPolarity = TIM_OCNPOLARITY_HIGH;
  sConfigOC.OCFastMode = TIM_OCFAST_DISABLE;
  sConfigOC.OCIdleState = TIM_OCIDLESTATE_RESET;
  sConfigOC.OCNIdleState = TIM_OCNIDLESTATE_RESET;
  if (HAL_TIM_PWM_ConfigChannel(&htim1, &sConfigOC, TIM_CHANNEL_1) != HAL_OK)
  {
    Error_Handler();
  }
  if (HAL_TIM_PWM_ConfigChannel(&htim1, &sConfigOC, TIM_CHANNEL_2) != HAL_OK)
  {
    Error_Handler();
  }
  if (HAL_TIM_PWM_ConfigChannel(&htim1, &sConfigOC, TIM_CHANNEL_3) != HAL_OK)
  {
    Error_Handler();
  }
  sConfigOC.Pulse = 1;
  if (HAL_TIM_PWM_ConfigChannel(&htim1, &sConfigOC, TIM_CHANNEL_4) != HAL_OK)
  {
    Error_Handler();
  }
  sBreakDeadTimeConfig.OffStateRunMode = TIM_OSSR_DISABLE;
  sBreakDeadTimeConfig.OffStateIDLEMode = TIM_OSSI_DISABLE;
  sBreakDeadTimeConfig.LockLevel = TIM_LOCKLEVEL_OFF;
  sBreakDeadTimeConfig.DeadTime = 0;
  sBreakDeadTimeConfig.BreakState = TIM_BREAK_DISABLE;
  sBreakDeadTimeConfig.BreakPolarity = TIM_BREAKPOLARITY_HIGH;
  sBreakDeadTimeConfig.BreakFilter = 0;
  sBreakDeadTimeConfig.Break2State = TIM_BREAK2_DISABLE;
  sBreakDeadTimeConfig.Break2Polarity = TIM_BREAK2POLARITY_HIGH;
  sBreakDeadTimeConfig.Break2Filter = 0;
  sBreakDeadTimeConfig.AutomaticOutput = TIM_AUTOMATICOUTPUT_DISABLE;
  if (HAL_TIMEx_ConfigBreakDeadTime(&htim1, &sBreakDeadTimeConfig) != HAL_OK)
  {
    Error_Handler();
  }
  HAL_TIM_MspPostInit(&htim1);

}

static void MX_TIM2_Init(void)
{

  TIM_ClockConfigTypeDef sClockSourceConfig = {0};
  TIM_MasterConfigTypeDef sMasterConfig = {0};
  TIM_OC_InitTypeDef sConfigOC = {0};

  htim2.Instance = TIM2;
  htim2.Init.Prescaler = 0;
  htim2.Init.CounterMode = TIM_COUNTERMODE_UP;
  htim2.Init.Period = 843750;
  htim2.Init.ClockDivision = TIM_CLOCKDIVISION_DIV1;
  htim2.Init.AutoReloadPreload = TIM_AUTORELOAD_PRELOAD_ENABLE;
  if (HAL_TIM_Base_Init(&htim2) != HAL_OK)
  {
    Error_Handler();
  }
  sClockSourceConfig.ClockSource = TIM_CLOCKSOURCE_INTERNAL;
  if (HAL_TIM_ConfigClockSource(&htim2, &sClockSourceConfig) != HAL_OK)
  {
    Error_Handler();
  }
  if (HAL_TIM_OC_Init(&htim2) != HAL_OK)
  {
    Error_Handler();
  }
  sMasterConfig.MasterOutputTrigger = TIM_TRGO_RESET;
  sMasterConfig.MasterSlaveMode = TIM_MASTERSLAVEMODE_DISABLE;
  if (HAL_TIMEx_MasterConfigSynchronization(&htim2, &sMasterConfig) != HAL_OK)
  {
    Error_Handler();
  }
  sConfigOC.OCMode = TIM_OCMODE_TIMING;
  sConfigOC.Pulse = 0;
  sConfigOC.OCPolarity = TIM_OCPOLARITY_HIGH;
  sConfigOC.OCFastMode = TIM_OCFAST_DISABLE;
  if (HAL_TIM_OC_ConfigChannel(&htim2, &sConfigOC, TIM_CHANNEL_1) != HAL_OK)
  {
    Error_Handler();
  }
  /* USER CODE BEGIN TIM2_Init 2 */
  HAL_TIM_RegisterCallback(&htim2, HAL_TIM_PERIOD_ELAPSED_CB_ID, SD_TIM2_PeriodElapsedCallback);
  __HAL_TIM_ENABLE_IT(&htim2, TIM_IT_UPDATE);
  /* USER CODE END TIM2_Init 2 */

}

static void MX_TIM3_Init(void)
{

  TIM_ClockConfigTypeDef sClockSourceConfig = {0};
  TIM_MasterConfigTypeDef sMasterConfig = {0};
  TIM_IC_InitTypeDef sConfigIC = {0};

  htim3.Instance = TIM3;
  htim3.Init.Prescaler = 0;
  htim3.Init.CounterMode = TIM_COUNTERMODE_UP;
  htim3.Init.Period = 65535;
  htim3.Init.ClockDivision = TIM_CLOCKDIVISION_DIV1;
  htim3.Init.AutoReloadPreload = TIM_AUTORELOAD_PRELOAD_DISABLE;
  if (HAL_TIM_Base_Init(&htim3) != HAL_OK)
  {
    Error_Handler();
  }
  sClockSourceConfig.ClockSource = TIM_CLOCKSOURCE_INTERNAL;
  if (HAL_TIM_ConfigClockSource(&htim3, &sClockSourceConfig) != HAL_OK)
  {
    Error_Handler();
  }
  if (HAL_TIM_IC_Init(&htim3) != HAL_OK)
  {
    Error_Handler();
  }
  sMasterConfig.MasterOutputTrigger = TIM_TRGO_RESET;
  sMasterConfig.MasterSlaveMode = TIM_MASTERSLAVEMODE_DISABLE;
  if (HAL_TIMEx_MasterConfigSynchronization(&htim3, &sMasterConfig) != HAL_OK)
  {
    Error_Handler();
  }
  sConfigIC.ICPolarity = TIM_INPUTCHANNELPOLARITY_RISING;
  sConfigIC.ICSelection = TIM_ICSELECTION_DIRECTTI;
  sConfigIC.ICPrescaler = TIM_ICPSC_DIV1;
  sConfigIC.ICFilter = 0;
  if (HAL_TIM_IC_ConfigChannel(&htim3, &sConfigIC, TIM_CHANNEL_1) != HAL_OK)
  {
    Error_Handler();
  }
  if (HAL_TIM_IC_ConfigChannel(&htim3, &sConfigIC, TIM_CHANNEL_2) != HAL_OK)
  {
    Error_Handler();
  }
  if (HAL_TIM_IC_ConfigChannel(&htim3, &sConfigIC, TIM_CHANNEL_3) != HAL_OK)
  {
    Error_Handler();
  }

}

static void MX_TIM4_Init(void)
{

  TIM_ClockConfigTypeDef sClockSourceConfig = {0};
  TIM_MasterConfigTypeDef sMasterConfig = {0};
  TIM_IC_InitTypeDef sConfigIC = {0};

  htim4.Instance = TIM4;
  htim4.Init.Prescaler = 0;
  htim4.Init.CounterMode = TIM_COUNTERMODE_UP;
  htim4.Init.Period = 65535;
  htim4.Init.ClockDivision = TIM_CLOCKDIVISION_DIV1;
  htim4.Init.AutoReloadPreload = TIM_AUTORELOAD_PRELOAD_DISABLE;
  if (HAL_TIM_Base_Init(&htim4) != HAL_OK)
  {
    Error_Handler();
  }
  sClockSourceConfig.ClockSource = TIM_CLOCKSOURCE_INTERNAL;
  if (HAL_TIM_ConfigClockSource(&htim4, &sClockSourceConfig) != HAL_OK)
  {
    Error_Handler();
  }
  if (HAL_TIM_IC_Init(&htim4) != HAL_OK)
  {
    Error_Handler();
  }
  sMasterConfig.MasterOutputTrigger = TIM_TRGO_RESET;
  sMasterConfig.MasterSlaveMode = TIM_MASTERSLAVEMODE_DISABLE;
  if (HAL_TIMEx_MasterConfigSynchronization(&htim4, &sMasterConfig) != HAL_OK)
  {
    Error_Handler();
  }
  sConfigIC.ICPolarity = TIM_INPUTCHANNELPOLARITY_RISING;
  sConfigIC.ICSelection = TIM_ICSELECTION_DIRECTTI;
  sConfigIC.ICPrescaler = TIM_ICPSC_DIV1;
  sConfigIC.ICFilter = 0;
  if (HAL_TIM_IC_ConfigChannel(&htim4, &sConfigIC, TIM_CHANNEL_1) != HAL_OK)
  {
    Error_Handler();
  }
  if (HAL_TIM_IC_ConfigChannel(&htim4, &sConfigIC, TIM_CHANNEL_2) != HAL_OK)
  {
    Error_Handler();
  }
  if (HAL_TIM_IC_ConfigChannel(&htim4, &sConfigIC, TIM_CHANNEL_3) != HAL_OK)
  {
    Error_Handler();
  }

}

static void MX_TIM5_Init(void)
{

  TIM_ClockConfigTypeDef sClockSourceConfig = {0};
  TIM_MasterConfigTypeDef sMasterConfig = {0};
  TIM_OC_InitTypeDef sConfigOC = {0};

  htim5.Instance = TIM5;
  htim5.Init.Prescaler = 0;
  htim5.Init.CounterMode = TIM_COUNTERMODE_UP;
  htim5.Init.Period = 843750;
  htim5.Init.ClockDivision = TIM_CLOCKDIVISION_DIV1;
  htim5.Init.AutoReloadPreload = TIM_AUTORELOAD_PRELOAD_DISABLE;
  if (HAL_TIM_Base_Init(&htim5) != HAL_OK)
  {
    Error_Handler();
  }
  sClockSourceConfig.ClockSource = TIM_CLOCKSOURCE_INTERNAL;
  if (HAL_TIM_ConfigClockSource(&htim5, &sClockSourceConfig) != HAL_OK)
  {
    Error_Handler();
  }
  if (HAL_TIM_OC_Init(&htim5) != HAL_OK)
  {
    Error_Handler();
  }
  sMasterConfig.MasterOutputTrigger = TIM_TRGO_RESET;
  sMasterConfig.MasterSlaveMode = TIM_MASTERSLAVEMODE_DISABLE;
  if (HAL_TIMEx_MasterConfigSynchronization(&htim5, &sMasterConfig) != HAL_OK)
  {
    Error_Handler();
  }
  sConfigOC.OCMode = TIM_OCMODE_TIMING;
  sConfigOC.Pulse = 0;
  sConfigOC.OCPolarity = TIM_OCPOLARITY_HIGH;
  sConfigOC.OCFastMode = TIM_OCFAST_DISABLE;
  if (HAL_TIM_OC_ConfigChannel(&htim5, &sConfigOC, TIM_CHANNEL_1) != HAL_OK)
  {
    Error_Handler();
  }
  /* USER CODE BEGIN TIM5_Init 2 */
  HAL_TIM_RegisterCallback(&htim5, HAL_TIM_PERIOD_ELAPSED_CB_ID, SD_TIM5_PeriodElapsedCallback);
  __HAL_TIM_ENABLE_IT(&htim5, TIM_IT_UPDATE);
  /* USER CODE END TIM5_Init 2 */

}

static void MX_TIM8_Init(void)
{

  TIM_ClockConfigTypeDef sClockSourceConfig = {0};
  TIM_SlaveConfigTypeDef sSlaveConfig = {0};
  TIM_MasterConfigTypeDef sMasterConfig = {0};
  TIM_OC_InitTypeDef sConfigOC = {0};
  TIM_BreakDeadTimeConfigTypeDef sBreakDeadTimeConfig = {0};

  htim8.Instance = TIM8;
  htim8.Init.Prescaler = 0;
  htim8.Init.CounterMode = TIM_COUNTERMODE_CENTERALIGNED3;
  htim8.Init.Period = TIM1_PERIOD_CLOCKS;
  htim8.Init.ClockDivision = TIM_CLOCKDIVISION_DIV1;
  htim8.Init.RepetitionCounter = TIM1_RCR;
  htim8.Init.AutoReloadPreload = TIM_AUTORELOAD_PRELOAD_ENABLE;
  if (HAL_TIM_Base_Init(&htim8) != HAL_OK)
  {
    Error_Handler();
  }
  sClockSourceConfig.ClockSource = TIM_CLOCKSOURCE_INTERNAL;
  if (HAL_TIM_ConfigClockSource(&htim8, &sClockSourceConfig) != HAL_OK)
  {
    Error_Handler();
  }
  if (HAL_TIM_PWM_Init(&htim8) != HAL_OK)
  {
    Error_Handler();
  }
  sSlaveConfig.SlaveMode = TIM_SLAVEMODE_TRIGGER;
  sSlaveConfig.InputTrigger = TIM_TS_ITR0;
  if (HAL_TIM_SlaveConfigSynchro(&htim8, &sSlaveConfig) != HAL_OK)
  {
    Error_Handler();
  }
  sMasterConfig.MasterOutputTrigger = TIM_TRGO_ENABLE;
  sMasterConfig.MasterOutputTrigger2 = TIM_TRGO2_UPDATE;
  sMasterConfig.MasterSlaveMode = TIM_MASTERSLAVEMODE_DISABLE;
  if (HAL_TIMEx_MasterConfigSynchronization(&htim8, &sMasterConfig) != HAL_OK)
  {
    Error_Handler();
  }
  sConfigOC.OCMode = TIM_OCMODE_PWM2;
  sConfigOC.Pulse = 0;
  sConfigOC.OCPolarity = TIM_OCPOLARITY_HIGH;
  sConfigOC.OCNPolarity = TIM_OCNPOLARITY_HIGH;
  sConfigOC.OCFastMode = TIM_OCFAST_DISABLE;
  sConfigOC.OCIdleState = TIM_OCIDLESTATE_RESET;
  sConfigOC.OCNIdleState = TIM_OCNIDLESTATE_RESET;
  if (HAL_TIM_PWM_ConfigChannel(&htim8, &sConfigOC, TIM_CHANNEL_1) != HAL_OK)
  {
    Error_Handler();
  }
  if (HAL_TIM_PWM_ConfigChannel(&htim8, &sConfigOC, TIM_CHANNEL_2) != HAL_OK)
  {
    Error_Handler();
  }
  if (HAL_TIM_PWM_ConfigChannel(&htim8, &sConfigOC, TIM_CHANNEL_3) != HAL_OK)
  {
    Error_Handler();
  }
  sBreakDeadTimeConfig.OffStateRunMode = TIM_OSSR_DISABLE;
  sBreakDeadTimeConfig.OffStateIDLEMode = TIM_OSSI_DISABLE;
  sBreakDeadTimeConfig.LockLevel = TIM_LOCKLEVEL_OFF;
  sBreakDeadTimeConfig.DeadTime = 0;
  sBreakDeadTimeConfig.BreakState = TIM_BREAK_DISABLE;
  sBreakDeadTimeConfig.BreakPolarity = TIM_BREAKPOLARITY_HIGH;
  sBreakDeadTimeConfig.BreakFilter = 0;
  sBreakDeadTimeConfig.Break2State = TIM_BREAK2_DISABLE;
  sBreakDeadTimeConfig.Break2Polarity = TIM_BREAK2POLARITY_HIGH;
  sBreakDeadTimeConfig.Break2Filter = 0;
  sBreakDeadTimeConfig.AutomaticOutput = TIM_AUTOMATICOUTPUT_DISABLE;
  if (HAL_TIMEx_ConfigBreakDeadTime(&htim8, &sBreakDeadTimeConfig) != HAL_OK)
  {
    Error_Handler();
  }
  HAL_TIM_MspPostInit(&htim8);

}

static void MX_TIM12_Init(void)
{

  TIM_ClockConfigTypeDef sClockSourceConfig = {0};

  htim12.Instance = TIM12;
  htim12.Init.Prescaler = 0;
  htim12.Init.CounterMode = TIM_COUNTERMODE_UP;
  htim12.Init.Period = 0xFFFF;
  htim12.Init.ClockDivision = TIM_CLOCKDIVISION_DIV1;
  htim12.Init.AutoReloadPreload = TIM_AUTORELOAD_PRELOAD_DISABLE;
  if (HAL_TIM_Base_Init(&htim12) != HAL_OK)
  {
    Error_Handler();
  }
  sClockSourceConfig.ClockSource = TIM_CLOCKSOURCE_INTERNAL;
  if (HAL_TIM_ConfigClockSource(&htim12, &sClockSourceConfig) != HAL_OK)
  {
    Error_Handler();
  }

}

static void MX_UART4_Init(void)
{

  huart4.Instance = UART4;
  huart4.Init.BaudRate = 115200;
  huart4.Init.WordLength = UART_WORDLENGTH_8B;
  huart4.Init.StopBits = UART_STOPBITS_1;
  huart4.Init.Parity = UART_PARITY_NONE;
  huart4.Init.Mode = UART_MODE_TX_RX;
  huart4.Init.HwFlowCtl = UART_HWCONTROL_NONE;
  huart4.Init.OverSampling = UART_OVERSAMPLING_16;
  huart4.Init.OneBitSampling = UART_ONE_BIT_SAMPLE_DISABLE;
  huart4.AdvancedInit.AdvFeatureInit = UART_ADVFEATURE_NO_INIT;
  if (HAL_RS485Ex_Init(&huart4, UART_DE_POLARITY_HIGH, 0, 0) != HAL_OK)
  {
    Error_Handler();
  }

}

static void MX_UART8_Init(void)
{

  huart8.Instance = UART8;
  huart8.Init.BaudRate = 115200;
  huart8.Init.WordLength = UART_WORDLENGTH_8B;
  huart8.Init.StopBits = UART_STOPBITS_1;
  huart8.Init.Parity = UART_PARITY_NONE;
  huart8.Init.Mode = UART_MODE_TX_RX;
  huart8.Init.HwFlowCtl = UART_HWCONTROL_NONE;
  huart8.Init.OverSampling = UART_OVERSAMPLING_16;
  huart8.Init.OneBitSampling = UART_ONE_BIT_SAMPLE_DISABLE;
  huart8.AdvancedInit.AdvFeatureInit = UART_ADVFEATURE_NO_INIT;
  if (HAL_UART_Init(&huart8) != HAL_OK)
  {
    Error_Handler();
  }

}

static void MX_USART1_UART_Init(void)
{

  huart1.Instance = USART1;
  huart1.Init.BaudRate = 115200;
  huart1.Init.WordLength = UART_WORDLENGTH_8B;
  huart1.Init.StopBits = UART_STOPBITS_1;
  huart1.Init.Parity = UART_PARITY_NONE;
  huart1.Init.Mode = UART_MODE_TX_RX;
  huart1.Init.HwFlowCtl = UART_HWCONTROL_NONE;
  huart1.Init.OverSampling = UART_OVERSAMPLING_8;
  huart1.Init.OneBitSampling = UART_ONE_BIT_SAMPLE_DISABLE;
  huart1.AdvancedInit.AdvFeatureInit = UART_ADVFEATURE_NO_INIT;
  if (HAL_UART_Init(&huart1) != HAL_OK)
  {
    Error_Handler();
  }

}

static void MX_USART2_UART_Init(void)
{

  huart2.Instance = USART2;
  huart2.Init.BaudRate = 2500000;
  huart2.Init.WordLength = UART_WORDLENGTH_8B;
  huart2.Init.StopBits = UART_STOPBITS_1;
  huart2.Init.Parity = UART_PARITY_NONE;
  huart2.Init.Mode = UART_MODE_TX_RX;
  huart2.Init.HwFlowCtl = UART_HWCONTROL_NONE;
  huart2.Init.OverSampling = UART_OVERSAMPLING_8;
  huart2.Init.OneBitSampling = UART_ONE_BIT_SAMPLE_DISABLE;
  huart2.AdvancedInit.AdvFeatureInit = UART_ADVFEATURE_NO_INIT;
  if (HAL_RS485Ex_Init(&huart2, UART_DE_POLARITY_HIGH, 0, 0) != HAL_OK)
  {
    Error_Handler();
  }

}

static void MX_USART3_UART_Init(void)
{

  huart3.Instance = USART3;
  huart3.Init.BaudRate = 2500000;
  huart3.Init.WordLength = UART_WORDLENGTH_8B;
  huart3.Init.StopBits = UART_STOPBITS_1;
  huart3.Init.Parity = UART_PARITY_NONE;
  huart3.Init.Mode = UART_MODE_TX_RX;
  huart3.Init.HwFlowCtl = UART_HWCONTROL_NONE;
  huart3.Init.OverSampling = UART_OVERSAMPLING_8;
  huart3.Init.OneBitSampling = UART_ONE_BIT_SAMPLE_DISABLE;
  huart3.AdvancedInit.AdvFeatureInit = UART_ADVFEATURE_NO_INIT;
  if (HAL_RS485Ex_Init(&huart3, UART_DE_POLARITY_HIGH, 0, 0) != HAL_OK)
  {
    Error_Handler();
  }

}

static void MX_DMA_Init(void)
{

  /* DMA controller clock enable */
  __HAL_RCC_DMA2_CLK_ENABLE();
  __HAL_RCC_DMA1_CLK_ENABLE();

  /* DMA interrupt init */
  /* DMA1_Stream0_IRQn interrupt configuration */
  HAL_NVIC_SetPriority(DMA1_Stream0_IRQn, 5, 0);
  HAL_NVIC_EnableIRQ(DMA1_Stream0_IRQn);
  /* DMA1_Stream1_IRQn interrupt configuration */
  HAL_NVIC_SetPriority(DMA1_Stream1_IRQn, 5, 0);
  HAL_NVIC_EnableIRQ(DMA1_Stream1_IRQn);
  /* DMA1_Stream2_IRQn interrupt configuration */
  HAL_NVIC_SetPriority(DMA1_Stream2_IRQn, 5, 0);
  HAL_NVIC_EnableIRQ(DMA1_Stream2_IRQn);
  /* DMA1_Stream4_IRQn interrupt configuration */
  HAL_NVIC_SetPriority(DMA1_Stream4_IRQn, 5, 0);
  HAL_NVIC_EnableIRQ(DMA1_Stream4_IRQn);
  /* DMA1_Stream5_IRQn interrupt configuration */
  HAL_NVIC_SetPriority(DMA1_Stream5_IRQn, 5, 0);
  HAL_NVIC_EnableIRQ(DMA1_Stream5_IRQn);
  /* DMA1_Stream6_IRQn interrupt configuration */
  HAL_NVIC_SetPriority(DMA1_Stream6_IRQn, 5, 0);
  HAL_NVIC_EnableIRQ(DMA1_Stream6_IRQn);
  /* DMA2_Stream0_IRQn interrupt configuration */
  HAL_NVIC_SetPriority(DMA2_Stream0_IRQn, 5, 0);
  HAL_NVIC_EnableIRQ(DMA2_Stream0_IRQn);
  /* DMA2_Stream2_IRQn interrupt configuration */
  HAL_NVIC_SetPriority(DMA2_Stream2_IRQn, 5, 0);
  HAL_NVIC_EnableIRQ(DMA2_Stream2_IRQn);
  /* DMA2_Stream5_IRQn interrupt configuration */
  HAL_NVIC_SetPriority(DMA2_Stream5_IRQn, 5, 0);
  HAL_NVIC_EnableIRQ(DMA2_Stream5_IRQn);
  /* DMA2_Stream7_IRQn interrupt configuration */
  HAL_NVIC_SetPriority(DMA2_Stream7_IRQn, 5, 0);
  HAL_NVIC_EnableIRQ(DMA2_Stream7_IRQn);

}

static void MX_GPIO_Init(void)
{
  GPIO_InitTypeDef GPIO_InitStruct = {0};

  /* GPIO Ports Clock Enable */
  __HAL_RCC_GPIOE_CLK_ENABLE();
  __HAL_RCC_GPIOC_CLK_ENABLE();
  __HAL_RCC_GPIOH_CLK_ENABLE();
  __HAL_RCC_GPIOA_CLK_ENABLE();
  __HAL_RCC_GPIOB_CLK_ENABLE();
  __HAL_RCC_GPIOD_CLK_ENABLE();

  /*Configure GPIO pin Output Level */
  HAL_GPIO_WritePin(GPIOE, GPIO_PIN_5|GPIO_PIN_6|GPIO_PIN_14, GPIO_PIN_RESET);

  /*Configure GPIO pin Output Level */
  HAL_GPIO_WritePin(GPIOC, GPIO_PIN_13|GPIO_PIN_14|LED_STATUS_Pin, GPIO_PIN_SET);

  /*Configure GPIO pin Output Level */
  HAL_GPIO_WritePin(GPIOB, GPIO_PIN_2, GPIO_PIN_SET);

  /*Configure GPIO pin Output Level */
  HAL_GPIO_WritePin(GPIOE, GPIO_PIN_15, GPIO_PIN_SET);

  /*Configure GPIO pin Output Level */
  HAL_GPIO_WritePin(LED_WARN_GPIO_Port, LED_WARN_Pin, GPIO_PIN_RESET);

  /*Configure GPIO pin Output Level */
  HAL_GPIO_WritePin(GPIOC, GPIO_PIN_12, GPIO_PIN_RESET);

  /*Configure GPIO pin Output Level */
  HAL_GPIO_WritePin(GPIOB, GPIO_PIN_9, GPIO_PIN_RESET);

  /*Configure GPIO pins : PE2 PE3 PE4 */
  GPIO_InitStruct.Pin = GPIO_PIN_2|GPIO_PIN_3|GPIO_PIN_4;
  GPIO_InitStruct.Mode = GPIO_MODE_INPUT;
  GPIO_InitStruct.Pull = GPIO_NOPULL;
  HAL_GPIO_Init(GPIOE, &GPIO_InitStruct);

  /*Configure GPIO pins : PE5 PE6 PE14 */
  GPIO_InitStruct.Pin = GPIO_PIN_5|GPIO_PIN_6|GPIO_PIN_14;
  GPIO_InitStruct.Mode = GPIO_MODE_OUTPUT_PP;
  GPIO_InitStruct.Pull = GPIO_NOPULL;
  GPIO_InitStruct.Speed = GPIO_SPEED_FREQ_LOW;
  HAL_GPIO_Init(GPIOE, &GPIO_InitStruct);

  /*Configure GPIO pins : PC13 PC14 */
  GPIO_InitStruct.Pin = GPIO_PIN_13|GPIO_PIN_14;
  GPIO_InitStruct.Mode = GPIO_MODE_OUTPUT_PP;
  GPIO_InitStruct.Pull = GPIO_PULLUP;
  GPIO_InitStruct.Speed = GPIO_SPEED_FREQ_LOW;
  HAL_GPIO_Init(GPIOC, &GPIO_InitStruct);

  /*Configure GPIO pin : PC15 */
  GPIO_InitStruct.Pin = GPIO_PIN_15;
  GPIO_InitStruct.Mode = GPIO_MODE_INPUT;
  GPIO_InitStruct.Pull = GPIO_PULLUP;
  HAL_GPIO_Init(GPIOC, &GPIO_InitStruct);

  /*Configure GPIO pin : PB2 */
  GPIO_InitStruct.Pin = GPIO_PIN_2;
  GPIO_InitStruct.Mode = GPIO_MODE_OUTPUT_PP;
  GPIO_InitStruct.Pull = GPIO_PULLUP;
  GPIO_InitStruct.Speed = GPIO_SPEED_FREQ_LOW;
  HAL_GPIO_Init(GPIOB, &GPIO_InitStruct);

  /*Configure GPIO pin : PE15 */
  GPIO_InitStruct.Pin = GPIO_PIN_15;
  GPIO_InitStruct.Mode = GPIO_MODE_OUTPUT_PP;
  GPIO_InitStruct.Pull = GPIO_PULLUP;
  GPIO_InitStruct.Speed = GPIO_SPEED_FREQ_LOW;
  HAL_GPIO_Init(GPIOE, &GPIO_InitStruct);

  /*Configure GPIO pins : PD10 PD11 PD0 PD1
                           PD2 PD3 */
  GPIO_InitStruct.Pin = GPIO_PIN_10|GPIO_PIN_11|GPIO_PIN_0|GPIO_PIN_1
                          |GPIO_PIN_2|GPIO_PIN_3;
  GPIO_InitStruct.Mode = GPIO_MODE_INPUT;
  GPIO_InitStruct.Pull = GPIO_NOPULL;
  HAL_GPIO_Init(GPIOD, &GPIO_InitStruct);

  /*Configure GPIO pin : LED_WARN_Pin */
  GPIO_InitStruct.Pin = LED_WARN_Pin;
  GPIO_InitStruct.Mode = GPIO_MODE_OUTPUT_PP;
  GPIO_InitStruct.Pull = GPIO_PULLUP;
  GPIO_InitStruct.Speed = GPIO_SPEED_FREQ_LOW;
  HAL_GPIO_Init(LED_WARN_GPIO_Port, &GPIO_InitStruct);

  /*Configure GPIO pins : LED_STATUS_Pin PC12 */
  GPIO_InitStruct.Pin = LED_STATUS_Pin|GPIO_PIN_12;
  GPIO_InitStruct.Mode = GPIO_MODE_OUTPUT_PP;
  GPIO_InitStruct.Pull = GPIO_NOPULL;
  GPIO_InitStruct.Speed = GPIO_SPEED_FREQ_LOW;
  HAL_GPIO_Init(GPIOC, &GPIO_InitStruct);

  /*Configure GPIO pin : USER_BTN_Pin */
  GPIO_InitStruct.Pin = USER_BTN_Pin;
  GPIO_InitStruct.Mode = GPIO_MODE_IT_FALLING;
  GPIO_InitStruct.Pull = GPIO_NOPULL;
  HAL_GPIO_Init(USER_BTN_GPIO_Port, &GPIO_InitStruct);

  /*Configure GPIO pin : ENCODER_Z_Pin */
  GPIO_InitStruct.Pin = ENCODER_Z_Pin;
  GPIO_InitStruct.Mode = GPIO_MODE_IT_RISING;
  GPIO_InitStruct.Pull = GPIO_PULLDOWN;
  HAL_GPIO_Init(ENCODER_Z_GPIO_Port, &GPIO_InitStruct);

  /*Configure GPIO pin : PB9 */
  GPIO_InitStruct.Pin = GPIO_PIN_9;
  GPIO_InitStruct.Mode = GPIO_MODE_OUTPUT_PP;
  GPIO_InitStruct.Pull = GPIO_NOPULL;
  GPIO_InitStruct.Speed = GPIO_SPEED_FREQ_LOW;
  HAL_GPIO_Init(GPIOB, &GPIO_InitStruct);

  /* EXTI interrupt init*/
  HAL_NVIC_SetPriority(EXTI9_5_IRQn, 2, 0);
  HAL_NVIC_EnableIRQ(EXTI9_5_IRQn);

}

void StartDefaultTask(void *argument)
{
  /* init code for USB_DEVICE */
  MX_USB_DEVICE_Init();
  /* USER CODE BEGIN 5 */
  /* Infinite loop */
  application_main();
  for(;;)
  {
    osDelay(1);
  }
  /* USER CODE END 5 */
}

void HAL_TIM_PeriodElapsedCallback(TIM_HandleTypeDef *htim)
{
  if (htim->Instance == TIM7) {
    HAL_IncTick();
  }
}

void Error_Handler(void)
{
}
